# ADuCM360 register map
Vendor: Analog Devices; Series: ARMCM3; File version: 0.7
CPU: CM3 r2p0, little endian, no MPU, no FPU, 3 interrupt priority bits
Registers are 16-bit, read-write, no defined reset value unless marked. A register's access mark holds for its fields unless they carry their own. Offsets are from the block's base; [hi:lo] are bit positions; {n}, {i} and the like mark numbered series; 'fields as' and 'values as' point back to an identical list.

## ADI_DMA — Direct Memory Access
Base 0x40010000
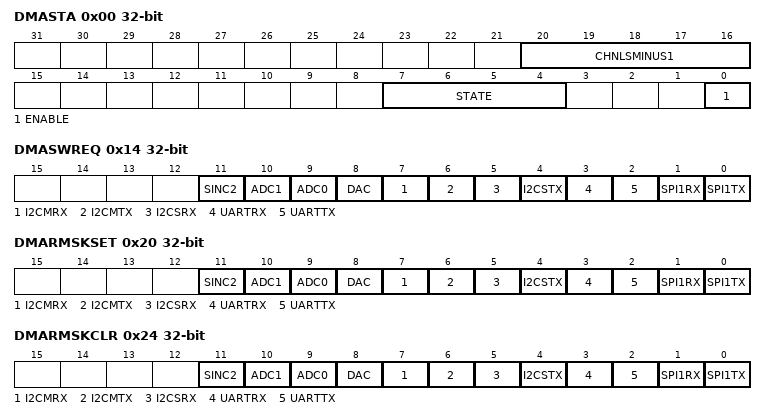
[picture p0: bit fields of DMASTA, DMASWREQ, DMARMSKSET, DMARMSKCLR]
0x00 DMASTA 32-bit — Returns the status of the controller when not in the reset state.
  [20:16] CHNLSMINUS1 — Number of available DMA channels minus one.
    13=FOURTEENCHNLS (- Controller configured to use 14 DMA channels); 11=TWELVECHNLS (- Controller configured to use 12 DMA channels)
  [7:4] STATE — Current state of the control state machine.
    0=IDLE; 1=RDCHNLDATA (- Reading channel controller data); 2=RDSRCENDPTR (- Reading source data end pointer); 3=RDDSTENDPTR (- Reading destination data end pointer); 4=RDSRCDATA (- Reading source data); 5=WRDSTDATA (- Writing destination data); 6=WAITDMAREQCLR (- Waiting for DMA request to clear); 7=WRCHNLDATA (- Writing channel controller data); 8=STALLED; 9=DONE; 10=SCATRGATHR (- Peripheral scatter-gather transition)
  [0] ENABLE — Master DMA controller enable status.
    0=CLR; 1=SET
0x04 DMACFG 32-bit — Configuraton
  [0] ENABLE — Master DMA controller enable
    0=DIS; 1=EN
0x08 DMAPDBPTR 32-bit — Channel primary control database pointer
  [31:0] CTRLBASEPTR — Pointer to the base address of the primary data structure
0x0C DMAADBPTR 32-bit — Channel alt control database pointer
  [31:0] ALTCBPTR — Pointer to the base address of the alternate data structure
0x14 DMASWREQ 32-bit — Channel Software Request
  [all] fields
    0=DIS; 1=EN
  [11] SINC2 — SINC2 Output Step detection
  [10] ADC1
  [9] ADC0
  [8] DAC — DAC DMA Output
  [7] I2CMRX — DMA I2C Master RX
  [6] I2CMTX — DMA I2C Master TX
  [5] I2CSRX — DMA I2C Slave RX
  [4] I2CSTX — DMA I2C Slave TX
  [3] UARTRX — DMA UART RX
  [2] UARTTX — DMA UART TX
  [1] SPI1RX — DMA SPI 1 RX
  [0] SPI1TX — DMA SPI 1 TX
0x20 DMARMSKSET 32-bit — Channel Request Mask Set
  fields as DMASWREQ
0x24 DMARMSKCLR 32-bit — Channel Request Mask Clear
  fields as DMASWREQ
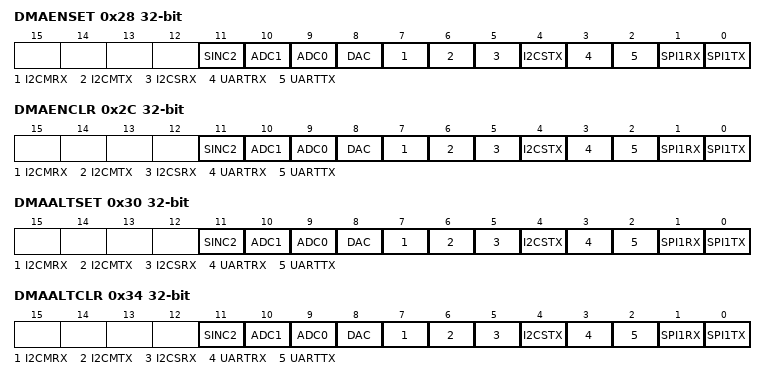
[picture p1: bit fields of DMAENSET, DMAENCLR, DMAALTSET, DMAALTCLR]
0x28 DMAENSET 32-bit — Channel Enable Set
  fields as DMASWREQ
0x2C DMAENCLR 32-bit — Channel Enable Clear
  fields as DMASWREQ
0x30 DMAALTSET 32-bit — Channel Primary-Alternate Set
  fields as DMASWREQ
0x34 DMAALTCLR 32-bit — Channel Primary-Alternate Clear
  fields as DMASWREQ
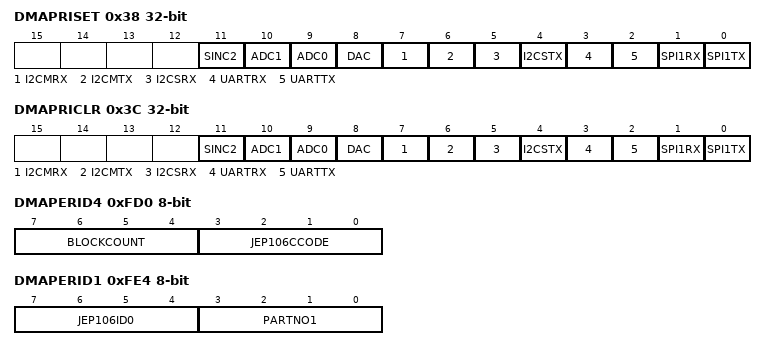
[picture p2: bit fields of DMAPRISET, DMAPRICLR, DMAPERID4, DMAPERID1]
0x38 DMAPRISET 32-bit — Channel Priority Set
  fields as DMASWREQ
0x3C DMAPRICLR 32-bit — Channel Priority Clear
  fields as DMASWREQ
0x4C DMAERRCLR 32-bit — Bus Error Clear
  [0] ERROR — DMA Error status
    0=DIS; 1=EN
0xFD0 DMAPERID4 8-bit — Peripheral identification 4
  [7:4] BLOCKCOUNT — The number of 4KB address blocks you require, to access the registers, expressed in powers of 2.
  [3:0] JEP106CCODE — The JEP106 continuation code value represents how many 0x7F continuation characters occur in the manufacturer?s identity code.
0xFE0 DMAPERID0 8-bit — Peripheral identification 0
  [7:0] PARTNO0 — Identifies the peripheral (part_number_0)
0xFE4 DMAPERID1 8-bit — Peripheral identification 1
  [7:4] JEP106ID0 — JEP106 identity code [3:0]
  [3:0] PARTNO1 — Identifies the peripheral (part_number_1)
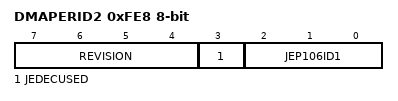
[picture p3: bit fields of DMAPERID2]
0xFE8 DMAPERID2 8-bit — Peripheral identification 2
  [7:4] REVISION — The revision status of the controller.
  [3] JEDECUSED — This indicates that the controller uses a manufacturer?s identity code that was allocated by JEDEC according to JEP106.
    0=DIS; 1=EN
  [2:0] JEP106ID1 — JEP106 identity code [6:4].
0xFEC DMAPERID3 8-bit — Peripheral identification 3
  [3:0] MODNUM — The customer must update this field if they modify the RTL of the controller.
{0xFF0+4i} DMAPCELLID{i} 8-bit (i=0..3) — PrimeCell identification {i}
  [7:0] PCELLID{i} — Primecell Identification

## ADI_ADCSTEP — Analog to Digital Converter
Base 0x400300E0
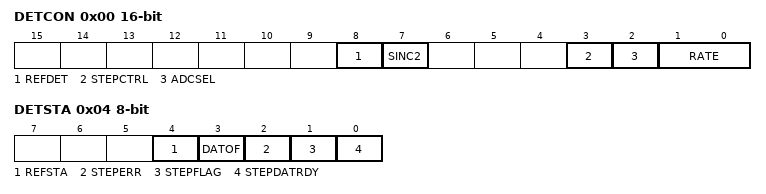
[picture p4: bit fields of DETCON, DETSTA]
0x00 DETCON — Control register for reference detection and the step detection filter
  [8] REFDET — Enable external reference detection circuit
    0=DIS; 1=EN
  [7] SINC2 — Enable Sinc2 filter
    0=DIS; 1=EN
  [3] STEPCTRL — Control the method to generate the step flag
    0=DIS; 1=EN
  [2] ADCSEL — Select ADC
    0=DIS; 1=EN
  [1:0] RATE — Control the sinc2 filter's time interval
0x04 DETSTA 8-bit — Status register for detection
  [all] fields
    0=DIS; 1=EN
  [4] REFSTA
  [3] DATOF — STEPDAT Overflow
  [2] STEPERR
  [1] STEPFLAG
  [0] STEPDATRDY
0x08 STEPTH — Threshold for step detection filter
  [8:0] VALUE
0x0C STEPDAT 32-bit — Offers coarse data from the output of the step detection filter
  [31:0] VALUE

## ADI_ADCDMA — Analog to Digital Converter
Base 0x400300F0
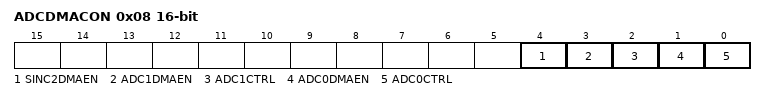
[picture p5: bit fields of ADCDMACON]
0x08 ADCDMACON — ADC DMA mode Configuration register
  [all] fields
    0=DIS; 1=EN
  [4] SINC2DMAEN
  [3] ADC1DMAEN
  [2] ADC1CTRL
  [1] ADC0DMAEN
  [0] ADC0CTRL

## ADI_DAC — Digital To Analog Converter
Base 0x40020000
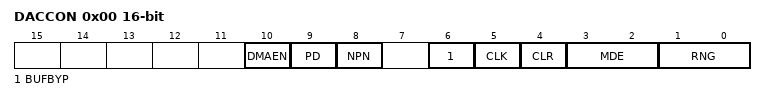
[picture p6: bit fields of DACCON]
0x00 DACCON — Control Register
  [10] DMAEN — bits
    0=Off; 1=On
  [9] PD
    0=DIS; 1=EN
  [8] NPN
    0=DIS; 1=EN
  [6] BUFBYP
    0=DIS; 1=EN
  [5] CLK — bits
    0=HCLK; 1=Timer1
  [4] CLR — bits
    1=Off; 0=On
  [3:2] MDE — Mode bits
    0=12bit; 3=16BitSlow; 2=16BitFast
  [1:0] RNG — DAC Range bits
    0=IntVref; 3=AVdd
0x04 DACDAT 32-bit — Data Register
  [31:12] VALUE — Data
